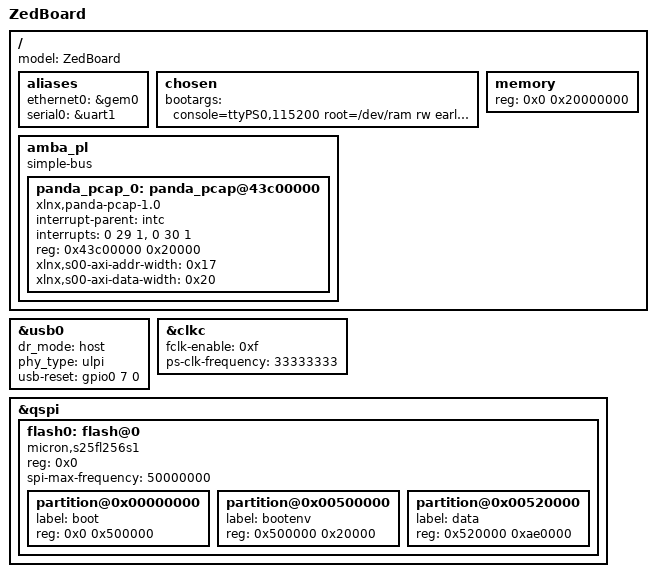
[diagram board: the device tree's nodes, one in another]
/dts-v1/;
/include/ "system-top.dts.tmp"

/ {
	model = "ZedBoard";
	aliases {
		ethernet0 = &gem0;
		serial0 = &uart1;
	};
	chosen {
		bootargs = "console=ttyPS0,115200 root=/dev/ram rw earlyprintk";
	};
	memory {
		device_type = "memory";
		reg = <0x0 0x20000000>;
	};
};

&usb0 {
	dr_mode = "host";
	phy_type = "ulpi";
	status = "okay";
	usb-reset = <&gpio0 7 0>;
};

&clkc {
	fclk-enable = <0xf>;
	ps-clk-frequency = <33333333>;
};

&qspi {
	#address-cells = <1>;
	#size-cells = <0>;
	flash0: flash@0 {
		compatible = "micron,s25fl256s1";
		reg = <0x0>;
		#address-cells = <1>;
		#size-cells = <1>;
		spi-max-frequency = <50000000>;
		partition@0x00000000 {
			label = "boot";
			reg = <0x0 0x500000>;
		};
		partition@0x00500000 {
			label = "bootenv";
			reg = <0x500000 0x20000>;
		};
		partition@0x00520000 {
			label = "data";
			reg = <0x520000 0xae0000>;
		};
	};
};

/ {
	amba_pl: amba_pl {
		#address-cells = <1>;
		#size-cells = <1>;
		compatible = "simple-bus";
		ranges ;
		panda_pcap_0: panda_pcap@43c00000 {
			compatible = "xlnx,panda-pcap-1.0";
			interrupt-parent = <&intc>;
			interrupts = <0 29 1>, <0 30 1>;
			reg = <0x43c00000 0x20000>;
			xlnx,s00-axi-addr-width = <0x17>;
			xlnx,s00-axi-data-width = <0x20>;
		};
	};
};
